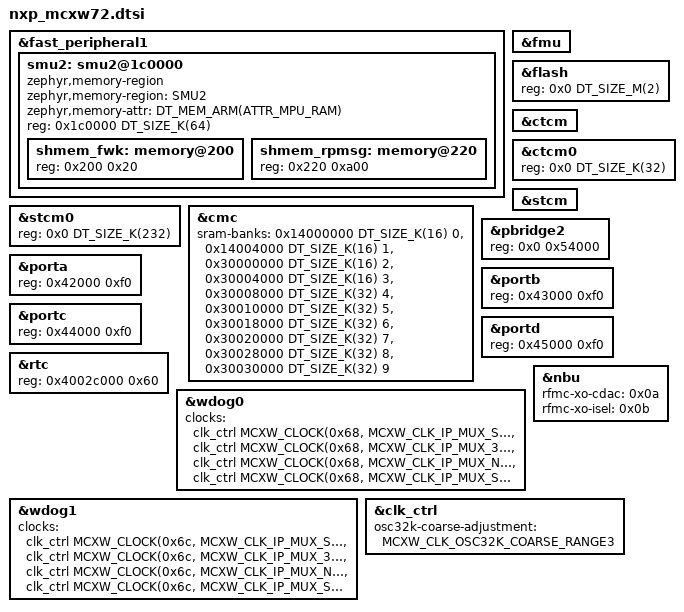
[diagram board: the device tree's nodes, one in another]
/*
 * Copyright 2024-2026 NXP
 *
 * SPDX-License-Identifier: Apache-2.0
 */

#include "nxp_mcxw7x_common.dtsi"

/* TSTMR is removed from MCXW72 due to SIRC clock source instability. */
/delete-node/ &tstmr0;

&fast_peripheral1 {
	smu2: smu2@1c0000 {
		ranges = <0x0 0x1c0000 DT_SIZE_K(80)>;
		#address-cells = <1>;
		#size-cells = <1>;
		compatible = "zephyr,memory-region", "mmio-sram";
		zephyr,memory-region = "SMU2";
		zephyr,memory-attr = <DT_MEM_ARM(ATTR_MPU_RAM)>;
		reg = <0x1c0000 DT_SIZE_K(64)>;

		shmem_fwk: memory@200 {
			reg = <0x200 0x20>;
		};

		shmem_rpmsg: memory@220 {
			reg = <0x220 0xa00>;
		};
	};
};

&fmu {
	ranges = <0x0 0x10000000 DT_SIZE_M(2)>;
};

&flash {
	reg = <0x0 DT_SIZE_M(2)>;
	ranges = <0x0 0x0 DT_SIZE_M(2)>;
};

&ctcm {
	ranges = <0x0 0x14000000 DT_SIZE_K(32)>;
};

&ctcm0 {
	reg = <0x0 DT_SIZE_K(32)>;
};

&stcm {
	ranges = <0x0 0x30000000 DT_SIZE_K(232)>;
};

&stcm0 {
	reg = <0x0 DT_SIZE_K(232)>;
};

&cmc {
	/*
	 * CMC SRAM power partitions: <start-address size cmc-disable-bit>.
	 * bits 0..1 Code-TCM (16 KB each @0x1400_0000);
	 * bits 2..9 System-TCM (16,16,32,32,32,32,32,32 KB @0x3000_0000).
	 * The top 8 KB VBAT-retained bank is intentionally omitted (never gated).
	 */
	sram-banks = <0x14000000 DT_SIZE_K(16) 0>,
		     <0x14004000 DT_SIZE_K(16) 1>,
		     <0x30000000 DT_SIZE_K(16) 2>,
		     <0x30004000 DT_SIZE_K(16) 3>,
		     <0x30008000 DT_SIZE_K(32) 4>,
		     <0x30010000 DT_SIZE_K(32) 5>,
		     <0x30018000 DT_SIZE_K(32) 6>,
		     <0x30020000 DT_SIZE_K(32) 7>,
		     <0x30028000 DT_SIZE_K(32) 8>,
		     <0x30030000 DT_SIZE_K(32) 9>;
};

&pbridge2 {
	reg = <0x0 0x54000>;
};

&porta {
	reg = <0x42000 0xf0>;
};

&portb {
	reg = <0x43000 0xf0>;
};

&portc {
	reg = <0x44000 0xf0>;
};

&portd {
	reg = <0x45000 0xf0>;
};

&rtc {
	reg = <0x4002c000 0x60>;
};

&wdog0 {
	clocks = <&clk_ctrl MCXW_CLOCK(0x68, MCXW_CLK_IP_MUX_SLOW_CLK,
				       MCXW_CLK_DIV_NONE,
				       MCXW_CLK_MODE_ENABLED_LP_STALL)>,
		 <&clk_ctrl MCXW_CLOCK(0x68, MCXW_CLK_IP_MUX_32K,
				       MCXW_CLK_DIV_NONE,
				       MCXW_CLK_MODE_ENABLED_LP_STALL)>,
		 <&clk_ctrl MCXW_CLOCK(0x68, MCXW_CLK_IP_MUX_NONE,
				       MCXW_CLK_DIV_NONE,
				       MCXW_CLK_MODE_DISABLED)>,
		 <&clk_ctrl MCXW_CLOCK(0x68, MCXW_CLK_IP_MUX_SOSC,
				       MCXW_CLK_DIV_NONE,
				       MCXW_CLK_MODE_ENABLED_LP_STALL)>;
	clock-names = "clksrc0", "clksrc1", "clksrc2", "clksrc3";
};

&wdog1 {
	clocks = <&clk_ctrl MCXW_CLOCK(0x6c, MCXW_CLK_IP_MUX_SLOW_CLK,
				       MCXW_CLK_DIV_NONE,
				       MCXW_CLK_MODE_ENABLED_LP_STALL)>,
		 <&clk_ctrl MCXW_CLOCK(0x6c, MCXW_CLK_IP_MUX_32K,
				       MCXW_CLK_DIV_NONE,
				       MCXW_CLK_MODE_ENABLED_LP_STALL)>,
		 <&clk_ctrl MCXW_CLOCK(0x6c, MCXW_CLK_IP_MUX_NONE,
				       MCXW_CLK_DIV_NONE,
				       MCXW_CLK_MODE_DISABLED)>,
		 <&clk_ctrl MCXW_CLOCK(0x6c, MCXW_CLK_IP_MUX_SOSC,
				       MCXW_CLK_DIV_NONE,
				       MCXW_CLK_MODE_ENABLED_LP_STALL)>;
	clock-names = "clksrc0", "clksrc1", "clksrc2", "clksrc3";
};

&nbu {
	rfmc-xo-cdac = <0x0a>;
	rfmc-xo-isel = <0x0b>;
};

&clk_ctrl {
	osc32k-coarse-adjustment = <MCXW_CLK_OSC32K_COARSE_RANGE3>;
};
